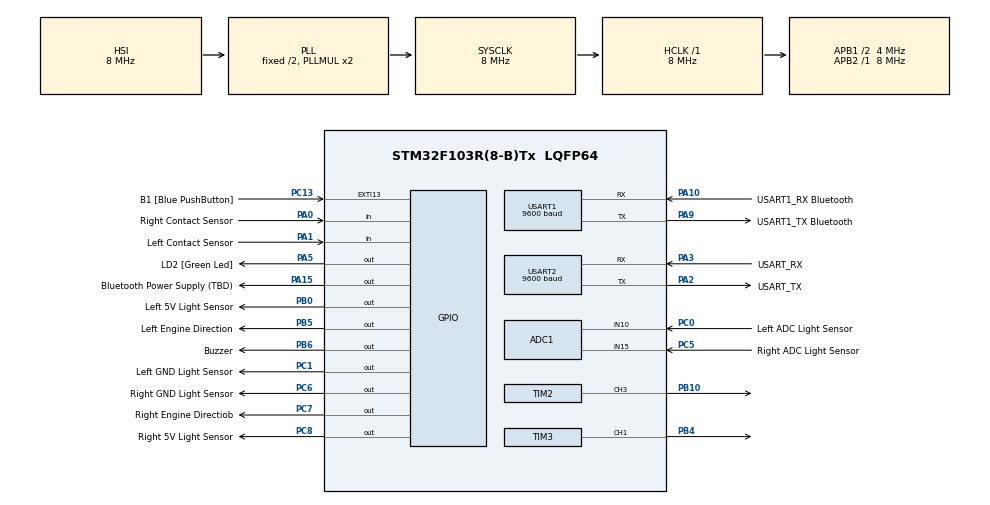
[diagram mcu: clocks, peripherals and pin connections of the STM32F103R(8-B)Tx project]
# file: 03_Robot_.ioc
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ADC1.Channel-1\#ChannelRegularConversion=ADC_CHANNEL_15
ADC1.ContinuousConvMode=DISABLE
ADC1.NbrOfConversion=1
ADC1.NbrOfConversionFlag=1
ADC1.Rank-1\#ChannelRegularConversion=1
ADC1.SamplingTime-1\#ChannelRegularConversion=ADC_SAMPLETIME_1CYCLE_5
ADC1.master=1
Mcu.Family=STM32F1
Mcu.Name=STM32F103R(8-B)Tx
Mcu.Package=LQFP64
NVIC.EXTI15_10_IRQn=true\:0\:0\:false\:false\:true\:true\:true
NVIC.PriorityGroup=NVIC_PRIORITYGROUP_4
NVIC.TIM4_IRQn=true\:0\:0\:false\:false\:true\:true\:true
PA0-WKUP.GPIO_Label=Right Contact Sensor
PA0-WKUP.GPIO_PuPd=GPIO_PULLUP
PA0-WKUP.Signal=GPIO_Input
PA1.GPIO_Label=Left Contact Sensor
PA1.GPIO_PuPd=GPIO_PULLUP
PA1.Signal=GPIO_Input
PA10.GPIO_Label=USART1_RX Bluetooth
PA10.Mode=Asynchronous
PA10.Signal=USART1_RX
PA13.GPIO_Label=TMS
PA13.Mode=Serial_Wire
PA13.Signal=SYS_JTMS-SWDIO
PA14.GPIO_Label=TCK
PA14.Mode=Serial_Wire
PA14.Signal=SYS_JTCK-SWCLK
PA15.GPIO_Label=Bluetooth Power Supply (TBD)
PA15.Signal=GPIO_Output
PA2.GPIO_Label=USART_TX
PA2.GPIO_Mode=GPIO_MODE_AF_PP
PA2.GPIO_PuPd=GPIO_NOPULL
PA2.GPIO_Speed=GPIO_SPEED_FREQ_LOW
PA2.Mode=Asynchronous
PA2.Signal=USART2_TX
PA3.GPIO_Label=USART_RX
PA3.GPIO_Mode=GPIO_MODE_AF_PP
PA3.GPIO_PuPd=GPIO_NOPULL
PA3.GPIO_Speed=GPIO_SPEED_FREQ_LOW
PA3.Mode=Asynchronous
PA3.Signal=USART2_RX
PA5.GPIO_Label=LD2 [Green Led]
PA5.GPIO_ModeDefaultOutputPP=GPIO_MODE_OUTPUT_PP
PA5.GPIO_PuPd=GPIO_NOPULL
PA5.GPIO_Speed=GPIO_SPEED_FREQ_LOW
PA5.Signal=GPIO_Output
PA9.GPIO_Label=USART1_TX Bluetooth
PA9.Mode=Asynchronous
PA9.Signal=USART1_TX
PB0.GPIO_Label=Left 5V Light Sensor
PB0.Signal=GPIO_Output
PB10.Signal=S_TIM2_CH3
PB3.GPIO_Label=SWO
PB3.Signal=SYS_JTDO-TRACESWO
PB4.Signal=S_TIM3_CH1
PB5.GPIO_Label=Left Engine Direction
PB5.Signal=GPIO_Output
PB6.GPIO_Label=Buzzer
PB6.Signal=GPIO_Output
PC0.GPIO_Label=Left ADC Light Sensor
PC0.Signal=SharedAnalog_PC0
PC1.GPIO_Label=Left GND Light Sensor
PC1.Signal=GPIO_Output
PC13-TAMPER-RTC.GPIO_Label=B1 [Blue PushButton]
PC13-TAMPER-RTC.GPIO_PuPd=GPIO_NOPULL
PC13-TAMPER-RTC.Signal=GPXTI13
PC14-OSC32_IN.Mode=LSE-External-Oscillator
PC14-OSC32_IN.Signal=RCC_OSC32_IN
PC15-OSC32_OUT.Mode=LSE-External-Oscillator
PC15-OSC32_OUT.Signal=RCC_OSC32_OUT
PC5.GPIO_Label=Right ADC Light Sensor
PC5.Signal=SharedAnalog_PC5
PC6.GPIO_Label=Right GND Light Sensor
PC6.Signal=GPIO_Output
PC7.GPIO_Label=Right Engine Directiob
PC7.Signal=GPIO_Output
PC8.GPIO_Label=Right 5V Light Sensor
PC8.Signal=GPIO_Output
PD0-OSC_IN.Mode=HSE-External-Clock-Source
PD0-OSC_IN.Signal=RCC_OSC_IN
PD1-OSC_OUT.Mode=HSE-External-Clock-Source
PD1-OSC_OUT.Signal=RCC_OSC_OUT
ProjectManager.HeapSize=0x200
ProjectManager.StackSize=0x400
ProjectManager.TargetToolchain=STM32CubeIDE
RCC.AHBFreq_Value=8000000
RCC.APB1CLKDivider=RCC_HCLK_DIV2
RCC.APB1Freq_Value=4000000
RCC.APB1TimFreq_Value=8000000
RCC.APB2Freq_Value=8000000
RCC.APB2TimFreq_Value=8000000
RCC.HCLKFreq_Value=8000000
RCC.RTCClockSelection=RCC_RTCCLKSOURCE_LSE
RCC.SYSCLKFreq_VALUE=8000000
RCC.SYSCLKSource=RCC_SYSCLKSOURCE_PLLCLK
RCC.USBFreq_Value=8000000
SH.S_TIM2_CH3.0=TIM2_CH3,PWM Generation3 CH3
SH.S_TIM3_CH1.0=TIM3_CH1,PWM Generation1 CH1
SH.SharedAnalog_PC0.0=GPIO_Analog
SH.SharedAnalog_PC0.1=ADC1_IN10,IN10
SH.SharedAnalog_PC5.0=GPIO_Analog
SH.SharedAnalog_PC5.1=ADC1_IN15,IN15
TIM2.Channel-PWM\ Generation3\ CH3=TIM_CHANNEL_3
TIM3.Channel-PWM\ Generation1\ CH1=TIM_CHANNEL_1
TIM4.Period=1000
TIM4.Prescaler=8000
USART1.BaudRate=9600
USART1.VirtualMode=VM_ASYNC
USART2.BaudRate=9600
USART2.VirtualMode=VM_ASYNC
VP_TIM2_VS_ClockSourceINT.Mode=Internal
VP_TIM3_VS_ClockSourceINT.Mode=Internal
VP_TIM4_VS_ClockSourceINT.Mode=Internal
board=NUCLEO-F103RB

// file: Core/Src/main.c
/* USER CODE BEGIN Header */
/**
  ******************************************************************************
  * @file           : main.c
  * @brief          : Main program body
  ******************************************************************************
  * @attention
  *
  * <h2><center>&copy; Copyright (c) 2020 STMicroelectronics.
  * All rights reserved.</center></h2>
  *
  * This software component is licensed by ST under BSD 3-Clause license,
  * the "License"; You may not use this file except in compliance with the
  * License. You may obtain a copy of the License at:
  *                        opensource.org/licenses/BSD-3-Clause
  *
  ******************************************************************************
  */
/* USER CODE END Header */
#include "main.h"

/* USER CODE BEGIN Includes */
#include "STM32_Robot.h"
/* USER CODE END Includes */

/* USER CODE BEGIN PD */
#define LED GPIO_PIN_5		//PA5
#define BUZZER GPIO_PIN_6	//PB6
#define BUTTON GPIO_PIN_10 	//PA10
#define MX SPD	40
/* USER CODE END PD */

ADC_HandleTypeDef hadc1;

TIM_HandleTypeDef htim2;
TIM_HandleTypeDef htim3;
TIM_HandleTypeDef htim4;

UART_HandleTypeDef huart1;
UART_HandleTypeDef huart2;

/* USER CODE BEGIN PV */
Robot rob;
/* USER CODE END PV */

void SystemClock_Config(void);
static void MX_GPIO_Init(void);
static void MX_USART2_UART_Init(void);
static void MX_TIM2_Init(void);
static void MX_TIM3_Init(void);
static void MX_USART1_UART_Init(void);
static void MX_ADC1_Init(void);
static void MX_TIM4_Init(void);

int main(void)
{

  /* MCU Configuration--------------------------------------------------------*/

  /* Reset of all peripherals, Initializes the Flash interface and the Systick. */
  HAL_Init();

  /* Configure the system clock */
  SystemClock_Config();

  /* Initialize all configured peripherals */
  MX_GPIO_Init();
  MX_USART2_UART_Init();
  MX_TIM2_Init();
  MX_TIM3_Init();
  MX_USART1_UART_Init();
  MX_ADC1_Init();
  MX_TIM4_Init();
  /* USER CODE BEGIN 2 */

  	  // initialize robot with default values
  	  robotDefaultValuesInit(&rob, &htim3, &htim2, &huart2, &huart1, &huart2, &hadc1);

  	  // start interrupts for timer to send robot telemetry to computer
  	  HAL_TIM_Base_Start_IT(&htim4);

  	  // perform start procedure
  	  robotStartProcedure(&rob);

  	  // start main program
  	  robotWallBouncer(&rob);
  /* USER CODE END 2 */

  /* Infinite loop */
  /* USER CODE BEGIN WHILE */

  // this loop should not be executed
  while (1)
  {

  }
    /* USER CODE END WHILE */

}

void SystemClock_Config(void)
{
  RCC_OscInitTypeDef RCC_OscInitStruct = {0};
  RCC_ClkInitTypeDef RCC_ClkInitStruct = {0};
  RCC_PeriphCLKInitTypeDef PeriphClkInit = {0};

  /** Initializes the RCC Oscillators according to the specified parameters
  * in the RCC_OscInitTypeDef structure.
  */
  RCC_OscInitStruct.OscillatorType = RCC_OSCILLATORTYPE_HSI;
  RCC_OscInitStruct.HSIState = RCC_HSI_ON;
  RCC_OscInitStruct.HSICalibrationValue = RCC_HSICALIBRATION_DEFAULT;
  RCC_OscInitStruct.PLL.PLLState = RCC_PLL_ON;
  RCC_OscInitStruct.PLL.PLLSource = RCC_PLLSOURCE_HSI_DIV2;
  RCC_OscInitStruct.PLL.PLLMUL = RCC_PLL_MUL2;
  if (HAL_RCC_OscConfig(&RCC_OscInitStruct) != HAL_OK)
  {
    Error_Handler();
  }
  /** Initializes the CPU, AHB and APB buses clocks
  */
  RCC_ClkInitStruct.ClockType = RCC_CLOCKTYPE_HCLK|RCC_CLOCKTYPE_SYSCLK
                              |RCC_CLOCKTYPE_PCLK1|RCC_CLOCKTYPE_PCLK2;
  RCC_ClkInitStruct.SYSCLKSource = RCC_SYSCLKSOURCE_PLLCLK;
  RCC_ClkInitStruct.AHBCLKDivider = RCC_SYSCLK_DIV1;
  RCC_ClkInitStruct.APB1CLKDivider = RCC_HCLK_DIV2;
  RCC_ClkInitStruct.APB2CLKDivider = RCC_HCLK_DIV1;

  if (HAL_RCC_ClockConfig(&RCC_ClkInitStruct, FLASH_LATENCY_0) != HAL_OK)
  {
    Error_Handler();
  }
  PeriphClkInit.PeriphClockSelection = RCC_PERIPHCLK_ADC;
  PeriphClkInit.AdcClockSelection = RCC_ADCPCLK2_DIV2;
  if (HAL_RCCEx_PeriphCLKConfig(&PeriphClkInit) != HAL_OK)
  {
    Error_Handler();
  }
}

static void MX_ADC1_Init(void)
{

  ADC_ChannelConfTypeDef sConfig = {0};

  /** Common config
  */
  hadc1.Instance = ADC1;
  hadc1.Init.ScanConvMode = ADC_SCAN_DISABLE;
  hadc1.Init.ContinuousConvMode = DISABLE;
  hadc1.Init.DiscontinuousConvMode = DISABLE;
  hadc1.Init.ExternalTrigConv = ADC_SOFTWARE_START;
  hadc1.Init.DataAlign = ADC_DATAALIGN_RIGHT;
  hadc1.Init.NbrOfConversion = 1;
  if (HAL_ADC_Init(&hadc1) != HAL_OK)
  {
    Error_Handler();
  }
  /** Configure Regular Channel
  */
  sConfig.Channel = ADC_CHANNEL_15;
  sConfig.Rank = ADC_REGULAR_RANK_1;
  sConfig.SamplingTime = ADC_SAMPLETIME_1CYCLE_5;
  if (HAL_ADC_ConfigChannel(&hadc1, &sConfig) != HAL_OK)
  {
    Error_Handler();
  }

}

static void MX_TIM2_Init(void)
{

  TIM_ClockConfigTypeDef sClockSourceConfig = {0};
  TIM_MasterConfigTypeDef sMasterConfig = {0};
  TIM_OC_InitTypeDef sConfigOC = {0};

  htim2.Instance = TIM2;
  htim2.Init.Prescaler = 0;
  htim2.Init.CounterMode = TIM_COUNTERMODE_UP;
  htim2.Init.Period = 65535;
  htim2.Init.ClockDivision = TIM_CLOCKDIVISION_DIV1;
  htim2.Init.AutoReloadPreload = TIM_AUTORELOAD_PRELOAD_DISABLE;
  if (HAL_TIM_Base_Init(&htim2) != HAL_OK)
  {
    Error_Handler();
  }
  sClockSourceConfig.ClockSource = TIM_CLOCKSOURCE_INTERNAL;
  if (HAL_TIM_ConfigClockSource(&htim2, &sClockSourceConfig) != HAL_OK)
  {
    Error_Handler();
  }
  if (HAL_TIM_PWM_Init(&htim2) != HAL_OK)
  {
    Error_Handler();
  }
  sMasterConfig.MasterOutputTrigger = TIM_TRGO_RESET;
  sMasterConfig.MasterSlaveMode = TIM_MASTERSLAVEMODE_DISABLE;
  if (HAL_TIMEx_MasterConfigSynchronization(&htim2, &sMasterConfig) != HAL_OK)
  {
    Error_Handler();
  }
  sConfigOC.OCMode = TIM_OCMODE_PWM1;
  sConfigOC.Pulse = 0;
  sConfigOC.OCPolarity = TIM_OCPOLARITY_HIGH;
  sConfigOC.OCFastMode = TIM_OCFAST_DISABLE;
  if (HAL_TIM_PWM_ConfigChannel(&htim2, &sConfigOC, TIM_CHANNEL_3) != HAL_OK)
  {
    Error_Handler();
  }
  HAL_TIM_MspPostInit(&htim2);

}

static void MX_TIM3_Init(void)
{

  TIM_ClockConfigTypeDef sClockSourceConfig = {0};
  TIM_MasterConfigTypeDef sMasterConfig = {0};
  TIM_OC_InitTypeDef sConfigOC = {0};

  htim3.Instance = TIM3;
  htim3.Init.Prescaler = 0;
  htim3.Init.CounterMode = TIM_COUNTERMODE_UP;
  htim3.Init.Period = 65535;
  htim3.Init.ClockDivision = TIM_CLOCKDIVISION_DIV1;
  htim3.Init.AutoReloadPreload = TIM_AUTORELOAD_PRELOAD_DISABLE;
  if (HAL_TIM_Base_Init(&htim3) != HAL_OK)
  {
    Error_Handler();
  }
  sClockSourceConfig.ClockSource = TIM_CLOCKSOURCE_INTERNAL;
  if (HAL_TIM_ConfigClockSource(&htim3, &sClockSourceConfig) != HAL_OK)
  {
    Error_Handler();
  }
  if (HAL_TIM_PWM_Init(&htim3) != HAL_OK)
  {
    Error_Handler();
  }
  sMasterConfig.MasterOutputTrigger = TIM_TRGO_RESET;
  sMasterConfig.MasterSlaveMode = TIM_MASTERSLAVEMODE_DISABLE;
  if (HAL_TIMEx_MasterConfigSynchronization(&htim3, &sMasterConfig) != HAL_OK)
  {
    Error_Handler();
  }
  sConfigOC.OCMode = TIM_OCMODE_PWM1;
  sConfigOC.Pulse = 0;
  sConfigOC.OCPolarity = TIM_OCPOLARITY_HIGH;
  sConfigOC.OCFastMode = TIM_OCFAST_DISABLE;
  if (HAL_TIM_PWM_ConfigChannel(&htim3, &sConfigOC, TIM_CHANNEL_1) != HAL_OK)
  {
    Error_Handler();
  }
  HAL_TIM_MspPostInit(&htim3);

}

static void MX_TIM4_Init(void)
{

  TIM_ClockConfigTypeDef sClockSourceConfig = {0};
  TIM_MasterConfigTypeDef sMasterConfig = {0};

  htim4.Instance = TIM4;
  htim4.Init.Prescaler = 8000;
  htim4.Init.CounterMode = TIM_COUNTERMODE_UP;
  htim4.Init.Period = 1000;
  htim4.Init.ClockDivision = TIM_CLOCKDIVISION_DIV1;
  htim4.Init.AutoReloadPreload = TIM_AUTORELOAD_PRELOAD_DISABLE;
  if (HAL_TIM_Base_Init(&htim4) != HAL_OK)
  {
    Error_Handler();
  }
  sClockSourceConfig.ClockSource = TIM_CLOCKSOURCE_INTERNAL;
  if (HAL_TIM_ConfigClockSource(&htim4, &sClockSourceConfig) != HAL_OK)
  {
    Error_Handler();
  }
  sMasterConfig.MasterOutputTrigger = TIM_TRGO_RESET;
  sMasterConfig.MasterSlaveMode = TIM_MASTERSLAVEMODE_DISABLE;
  if (HAL_TIMEx_MasterConfigSynchronization(&htim4, &sMasterConfig) != HAL_OK)
  {
    Error_Handler();
  }

}

static void MX_USART1_UART_Init(void)
{

  huart1.Instance = USART1;
  huart1.Init.BaudRate = 9600;
  huart1.Init.WordLength = UART_WORDLENGTH_8B;
  huart1.Init.StopBits = UART_STOPBITS_1;
  huart1.Init.Parity = UART_PARITY_NONE;
  huart1.Init.Mode = UART_MODE_TX_RX;
  huart1.Init.HwFlowCtl = UART_HWCONTROL_NONE;
  huart1.Init.OverSampling = UART_OVERSAMPLING_16;
  if (HAL_UART_Init(&huart1) != HAL_OK)
  {
    Error_Handler();
  }

}

static void MX_USART2_UART_Init(void)
{

  huart2.Instance = USART2;
  huart2.Init.BaudRate = 9600;
  huart2.Init.WordLength = UART_WORDLENGTH_8B;
  huart2.Init.StopBits = UART_STOPBITS_1;
  huart2.Init.Parity = UART_PARITY_NONE;
  huart2.Init.Mode = UART_MODE_TX_RX;
  huart2.Init.HwFlowCtl = UART_HWCONTROL_NONE;
  huart2.Init.OverSampling = UART_OVERSAMPLING_16;
  if (HAL_UART_Init(&huart2) != HAL_OK)
  {
    Error_Handler();
  }

}

static void MX_GPIO_Init(void)
{
  GPIO_InitTypeDef GPIO_InitStruct = {0};

  /* GPIO Ports Clock Enable */
  __HAL_RCC_GPIOC_CLK_ENABLE();
  __HAL_RCC_GPIOD_CLK_ENABLE();
  __HAL_RCC_GPIOA_CLK_ENABLE();
  __HAL_RCC_GPIOB_CLK_ENABLE();

  /*Configure GPIO pin Output Level */
  HAL_GPIO_WritePin(GPIOC, Left_GND_Light_Sensor_Pin|Right_GND_Light_Sensor_Pin|Right_Engine_Directiob_Pin|Right_5V_Light_Sensor_Pin, GPIO_PIN_RESET);

  /*Configure GPIO pin Output Level */
  HAL_GPIO_WritePin(GPIOA, LD2_Pin|Bluetooth_Power_Supply_Pin, GPIO_PIN_RESET);

  /*Configure GPIO pin Output Level */
  HAL_GPIO_WritePin(GPIOB, Left_5V_Light_Sensor_Pin|Left_Engine_Direction_Pin|Buzzer_Pin, GPIO_PIN_RESET);

  /*Configure GPIO pin : B1_Pin */
  GPIO_InitStruct.Pin = B1_Pin;
  GPIO_InitStruct.Mode = GPIO_MODE_IT_RISING;
  GPIO_InitStruct.Pull = GPIO_NOPULL;
  HAL_GPIO_Init(B1_GPIO_Port, &GPIO_InitStruct);

  /*Configure GPIO pins : Left_GND_Light_Sensor_Pin Right_GND_Light_Sensor_Pin Right_Engine_Directiob_Pin Right_5V_Light_Sensor_Pin */
  GPIO_InitStruct.Pin = Left_GND_Light_Sensor_Pin|Right_GND_Light_Sensor_Pin|Right_Engine_Directiob_Pin|Right_5V_Light_Sensor_Pin;
  GPIO_InitStruct.Mode = GPIO_MODE_OUTPUT_PP;
  GPIO_InitStruct.Pull = GPIO_NOPULL;
  GPIO_InitStruct.Speed = GPIO_SPEED_FREQ_LOW;
  HAL_GPIO_Init(GPIOC, &GPIO_InitStruct);

  /*Configure GPIO pins : Right_Contact_Sensor_Pin Left_Contact_Sensor_Pin */
  GPIO_InitStruct.Pin = Right_Contact_Sensor_Pin|Left_Contact_Sensor_Pin;
  GPIO_InitStruct.Mode = GPIO_MODE_INPUT;
  GPIO_InitStruct.Pull = GPIO_PULLUP;
  HAL_GPIO_Init(GPIOA, &GPIO_InitStruct);

  /*Configure GPIO pins : LD2_Pin Bluetooth_Power_Supply_Pin */
  GPIO_InitStruct.Pin = LD2_Pin|Bluetooth_Power_Supply_Pin;
  GPIO_InitStruct.Mode = GPIO_MODE_OUTPUT_PP;
  GPIO_InitStruct.Pull = GPIO_NOPULL;
  GPIO_InitStruct.Speed = GPIO_SPEED_FREQ_LOW;
  HAL_GPIO_Init(GPIOA, &GPIO_InitStruct);

  /*Configure GPIO pins : Left_5V_Light_Sensor_Pin Left_Engine_Direction_Pin Buzzer_Pin */
  GPIO_InitStruct.Pin = Left_5V_Light_Sensor_Pin|Left_Engine_Direction_Pin|Buzzer_Pin;
  GPIO_InitStruct.Mode = GPIO_MODE_OUTPUT_PP;
  GPIO_InitStruct.Pull = GPIO_NOPULL;
  GPIO_InitStruct.Speed = GPIO_SPEED_FREQ_LOW;
  HAL_GPIO_Init(GPIOB, &GPIO_InitStruct);

  /* EXTI interrupt init*/
  HAL_NVIC_SetPriority(EXTI15_10_IRQn, 0, 0);
  HAL_NVIC_EnableIRQ(EXTI15_10_IRQn);

}

/* USER CODE BEGIN 4 */
 void HAL_TIM_PeriodElapsedCallback(TIM_HandleTypeDef *htim)
 {
	 // every 1 second send data to computer
	 robotTelemetry(&rob);
 }
/* USER CODE END 4 */

void Error_Handler(void)
{
  __disable_irq();
  while (1)
  {
  }
}

/************************ (C) COPYRIGHT STMicroelectronics *****END OF FILE****/
